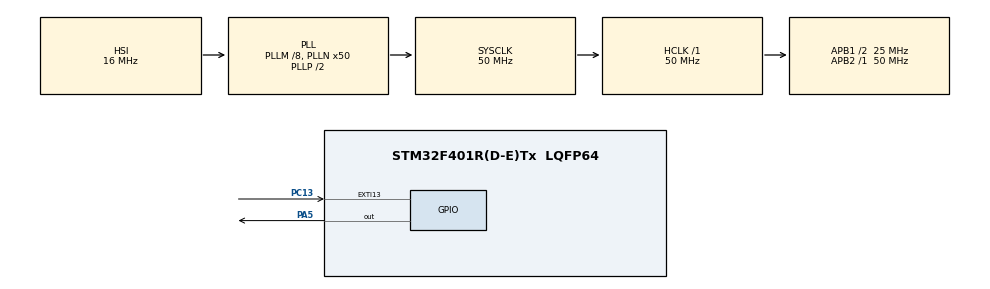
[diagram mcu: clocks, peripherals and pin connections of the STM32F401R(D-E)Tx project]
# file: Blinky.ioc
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Mcu.Family=STM32F4
Mcu.Name=STM32F401R(D-E)Tx
Mcu.Package=LQFP64
NVIC.PriorityGroup=NVIC_PRIORITYGROUP_0
PA10.Signal=S_TIM1_CH3
PA13.Mode=Serial_Wire
PA13.Signal=SYS_JTMS-SWDIO
PA14.Mode=Serial_Wire
PA14.Signal=SYS_JTCK-SWCLK
PA5.Signal=GPIO_Output
PC13-ANTI_TAMP.GPIO_PuPd=GPIO_PULLDOWN
PC13-ANTI_TAMP.Signal=GPXTI13
PH0\ -\ OSC_IN.Mode=HSE-External-Oscillator
PH0\ -\ OSC_IN.Signal=RCC_OSC_IN
PH1\ -\ OSC_OUT.Mode=HSE-External-Oscillator
PH1\ -\ OSC_OUT.Signal=RCC_OSC_OUT
ProjectManager.HeapSize=0x200
ProjectManager.StackSize=0x400
ProjectManager.TargetToolchain=STM32CubeIDE
RCC.48MHZClocksFreq_Value=14285714.285714285
RCC.AHBFreq_Value=50000000
RCC.APB1CLKDivider=RCC_HCLK_DIV2
RCC.APB1Freq_Value=25000000
RCC.APB1TimFreq_Value=50000000
RCC.APB2Freq_Value=50000000
RCC.APB2TimFreq_Value=50000000
RCC.CortexFreq_Value=50000000
RCC.HCLKFreq_Value=50000000
RCC.HSE_VALUE=8000000
RCC.HSI_VALUE=16000000
RCC.LSE_VALUE=32768
RCC.PLLM=8
RCC.PLLN=50
RCC.PLLQ=7
RCC.RCC_RTC_Clock_Source_FROM_HSE=RCC_RTCCLKSOURCE_HSE_DIV8
RCC.SYSCLKFreq_VALUE=50000000
RCC.SYSCLKSource=RCC_SYSCLKSOURCE_PLLCLK
RCC.VCOOutputFreq_Value=100000000
SH.S_TIM1_CH3.0=TIM1_CH3
board=NUCLEO-F401RE

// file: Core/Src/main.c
/* USER CODE BEGIN Header */
/**
  ******************************************************************************
  * @file           : main.c
  * @brief          : Main program body
  ******************************************************************************
  * @attention
  *
  * Copyright (c) 2022 STMicroelectronics.
  * All rights reserved.
  *
  * This software is licensed under terms that can be found in the LICENSE file
  * in the root directory of this software component.
  * If no LICENSE file comes with this software, it is provided AS-IS.
  *
  ******************************************************************************
  */
/* USER CODE END Header */
#include "main.h"

void SystemClock_Config(void);
static void MX_GPIO_Init(void);

int main(void)
{
  /* USER CODE BEGIN 1 */
	uint16_t prev_state = 0;
  /* USER CODE END 1 */

  /* MCU Configuration--------------------------------------------------------*/

  /* Reset of all peripherals, Initializes the Flash interface and the Systick. */
  HAL_Init();

  /* Configure the system clock */
  SystemClock_Config();

  /* Initialize all configured peripherals */
  MX_GPIO_Init();

  /* Infinite loop */
  while (1)
  {

    /* USER CODE BEGIN 3 */
		uint16_t read_state = HAL_GPIO_ReadPin(GPIOC, GPIO_PIN_13);
		if ((prev_state == 0 && read_state == 1) || (prev_state == 1 && read_state == 0)){
			if (prev_state == 1)
				prev_state = 0;
			for(int i = 1; i <= 1000; i++){
											HAL_GPIO_WritePin(GPIOA, GPIO_PIN_5, 1);
						}
						for(int i = 1; i <= 1000; i++){
								HAL_GPIO_WritePin(GPIOA, GPIO_PIN_5, 0);
						}

			}

		if ((prev_state == 1 && read_state == 1) || (prev_state == 0 && read_state == 0)){
			if (prev_state == 0)
				prev_state = 1;
			for(int i = 1;; i++){
						HAL_GPIO_WritePin(GPIOA, GPIO_PIN_5, 0);
						if (HAL_GPIO_ReadPin(GPIOC, GPIO_PIN_13) == 1)
						{
							break;
						}
			}
		}
		//HAL_GPIO_WritePin(GPIOA, GPIO_PIN_5, 1);
  }
  /* USER CODE END 3 */
}

void SystemClock_Config(void)
{
  RCC_OscInitTypeDef RCC_OscInitStruct = {0};
  RCC_ClkInitTypeDef RCC_ClkInitStruct = {0};

  /** Configure the main internal regulator output voltage
  */
  __HAL_RCC_PWR_CLK_ENABLE();
  __HAL_PWR_VOLTAGESCALING_CONFIG(PWR_REGULATOR_VOLTAGE_SCALE2);

  /** Initializes the RCC Oscillators according to the specified parameters
  * in the RCC_OscInitTypeDef structure.
  */
  RCC_OscInitStruct.OscillatorType = RCC_OSCILLATORTYPE_HSI;
  RCC_OscInitStruct.HSIState = RCC_HSI_ON;
  RCC_OscInitStruct.HSICalibrationValue = RCC_HSICALIBRATION_DEFAULT;
  RCC_OscInitStruct.PLL.PLLState = RCC_PLL_ON;
  RCC_OscInitStruct.PLL.PLLSource = RCC_PLLSOURCE_HSI;
  RCC_OscInitStruct.PLL.PLLM = 8;
  RCC_OscInitStruct.PLL.PLLN = 50;
  RCC_OscInitStruct.PLL.PLLP = RCC_PLLP_DIV2;
  RCC_OscInitStruct.PLL.PLLQ = 7;
  if (HAL_RCC_OscConfig(&RCC_OscInitStruct) != HAL_OK)
  {
    Error_Handler();
  }

  /** Initializes the CPU, AHB and APB buses clocks
  */
  RCC_ClkInitStruct.ClockType = RCC_CLOCKTYPE_HCLK|RCC_CLOCKTYPE_SYSCLK
                              |RCC_CLOCKTYPE_PCLK1|RCC_CLOCKTYPE_PCLK2;
  RCC_ClkInitStruct.SYSCLKSource = RCC_SYSCLKSOURCE_PLLCLK;
  RCC_ClkInitStruct.AHBCLKDivider = RCC_SYSCLK_DIV1;
  RCC_ClkInitStruct.APB1CLKDivider = RCC_HCLK_DIV2;
  RCC_ClkInitStruct.APB2CLKDivider = RCC_HCLK_DIV1;

  if (HAL_RCC_ClockConfig(&RCC_ClkInitStruct, FLASH_LATENCY_1) != HAL_OK)
  {
    Error_Handler();
  }
}

static void MX_GPIO_Init(void)
{
  GPIO_InitTypeDef GPIO_InitStruct = {0};

  /* GPIO Ports Clock Enable */
  __HAL_RCC_GPIOC_CLK_ENABLE();
  __HAL_RCC_GPIOH_CLK_ENABLE();
  __HAL_RCC_GPIOA_CLK_ENABLE();

  /*Configure GPIO pin Output Level */
  HAL_GPIO_WritePin(GPIOA, GPIO_PIN_5, GPIO_PIN_RESET);

  /*Configure GPIO pin : PC13 */
  GPIO_InitStruct.Pin = GPIO_PIN_13;
  GPIO_InitStruct.Mode = GPIO_MODE_IT_RISING;
  GPIO_InitStruct.Pull = GPIO_PULLDOWN;
  HAL_GPIO_Init(GPIOC, &GPIO_InitStruct);

  /*Configure GPIO pin : PA5 */
  GPIO_InitStruct.Pin = GPIO_PIN_5;
  GPIO_InitStruct.Mode = GPIO_MODE_OUTPUT_PP;
  GPIO_InitStruct.Pull = GPIO_NOPULL;
  GPIO_InitStruct.Speed = GPIO_SPEED_FREQ_LOW;
  HAL_GPIO_Init(GPIOA, &GPIO_InitStruct);

  /*Configure GPIO pin : PA10 */
  GPIO_InitStruct.Pin = GPIO_PIN_10;
  GPIO_InitStruct.Mode = GPIO_MODE_AF_PP;
  GPIO_InitStruct.Pull = GPIO_NOPULL;
  GPIO_InitStruct.Speed = GPIO_SPEED_FREQ_LOW;
  GPIO_InitStruct.Alternate = GPIO_AF1_TIM1;
  HAL_GPIO_Init(GPIOA, &GPIO_InitStruct);

}

void Error_Handler(void)
{
  __disable_irq();
  while (1)
  {
  }
}
